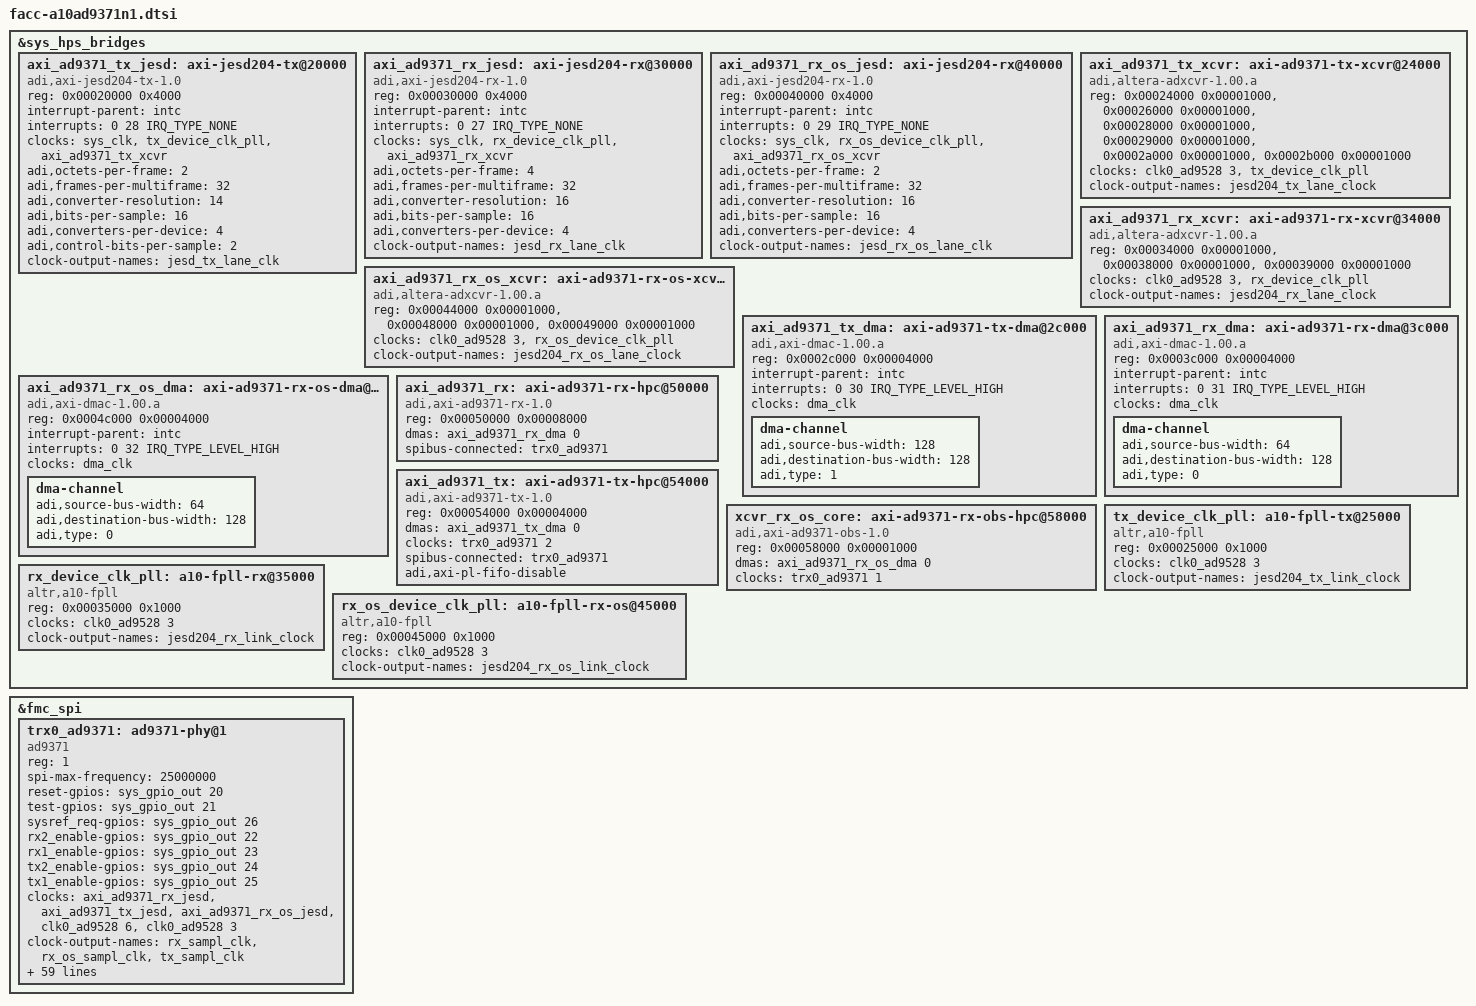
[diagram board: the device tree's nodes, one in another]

&sys_hps_bridges {
	axi_ad9371_tx_jesd: axi-jesd204-tx@20000 {
		compatible = "adi,axi-jesd204-tx-1.0";
		reg = <0x00020000 0x4000>;

		interrupt-parent = <&intc>;
		interrupts = <0 28 IRQ_TYPE_NONE>;

		clocks = <&sys_clk>, <&tx_device_clk_pll>, <&axi_ad9371_tx_xcvr>;
		clock-names = "s_axi_aclk", "device_clk", "lane_clk";

		adi,octets-per-frame = <2>;
		adi,frames-per-multiframe = <32>;
		adi,converter-resolution = <14>;
		adi,bits-per-sample = <16>;
		adi,converters-per-device = <4>;
		adi,control-bits-per-sample = <2>;

		#clock-cells = <0>;
		clock-output-names = "jesd_tx_lane_clk";
	};

	axi_ad9371_rx_jesd: axi-jesd204-rx@30000 {
		compatible = "adi,axi-jesd204-rx-1.0";
		reg = <0x00030000 0x4000>;

		interrupt-parent = <&intc>;
		interrupts = <0 27 IRQ_TYPE_NONE>;

		clocks = <&sys_clk>, <&rx_device_clk_pll>, <&axi_ad9371_rx_xcvr>;
		clock-names = "s_axi_aclk", "device_clk", "lane_clk";

		adi,octets-per-frame = <4>;
		adi,frames-per-multiframe = <32>;
		adi,converter-resolution = <16>;
		adi,bits-per-sample = <16>;
		adi,converters-per-device = <4>;

		#clock-cells = <0>;
		clock-output-names = "jesd_rx_lane_clk";
	};

	axi_ad9371_rx_os_jesd: axi-jesd204-rx@40000 {
		compatible = "adi,axi-jesd204-rx-1.0";
		reg = <0x00040000 0x4000>;

		interrupt-parent = <&intc>;
		interrupts = <0 29 IRQ_TYPE_NONE>;

		clocks = <&sys_clk>, <&rx_os_device_clk_pll>, <&axi_ad9371_rx_os_xcvr>;
		clock-names = "s_axi_aclk", "device_clk", "lane_clk";

		adi,octets-per-frame = <2>;
		adi,frames-per-multiframe = <32>;
		adi,converter-resolution = <16>;
		adi,bits-per-sample = <16>;
		adi,converters-per-device = <4>;

		#clock-cells = <0>;
		clock-output-names = "jesd_rx_os_lane_clk";
	};

	axi_ad9371_tx_xcvr: axi-ad9371-tx-xcvr@24000 {
		compatible = "adi,altera-adxcvr-1.00.a";
		reg = <0x00024000 0x00001000>,
			<0x00026000 0x00001000>,
			<0x00028000 0x00001000>,
			<0x00029000 0x00001000>,
			<0x0002a000 0x00001000>,
			<0x0002b000 0x00001000>;
		reg-names = "adxcvr", "atx-pll", "adxcfg-0", "adxcfg-1", "adxcfg-2", "adxcfg-3";

		clocks = <&clk0_ad9528 3>, <&tx_device_clk_pll>;
		clock-names = "ref", "link";

		#clock-cells = <0>;
		clock-output-names = "jesd204_tx_lane_clock";
	};

	axi_ad9371_rx_xcvr: axi-ad9371-rx-xcvr@34000 {
		compatible = "adi,altera-adxcvr-1.00.a";
		reg = <0x00034000 0x00001000>,
			<0x00038000 0x00001000>,
			<0x00039000 0x00001000>;
		reg-names = "adxcvr", "adxcfg-0", "adxcfg-1";

		clocks = <&clk0_ad9528 3>, <&rx_device_clk_pll>;
		clock-names = "ref", "link";

		#clock-cells = <0>;
		clock-output-names = "jesd204_rx_lane_clock";
	};

	axi_ad9371_rx_os_xcvr: axi-ad9371-rx-os-xcvr@44000 {
		compatible = "adi,altera-adxcvr-1.00.a";
		reg = <0x00044000 0x00001000>,
			<0x00048000 0x00001000>,
			<0x00049000 0x00001000>;
		reg-names = "adxcvr", "adxcfg-0", "adxcfg-1";

		clocks = <&clk0_ad9528 3>, <&rx_os_device_clk_pll>;
		clock-names = "ref", "link";

		#clock-cells = <0>;
		clock-output-names = "jesd204_rx_os_lane_clock";
	};

	axi_ad9371_tx_dma: axi-ad9371-tx-dma@2c000 {
		compatible = "adi,axi-dmac-1.00.a";
		reg = <0x0002c000 0x00004000>;
		interrupt-parent = <&intc>;
		interrupts = <0 30 IRQ_TYPE_LEVEL_HIGH>;
		#dma-cells = <1>;
		clocks = <&dma_clk>;

		dma-channel {
			adi,source-bus-width = <128>;
			adi,destination-bus-width = <128>;
			adi,type = <1>;
			//adi,cyclic;
		};
	};

	axi_ad9371_rx_dma: axi-ad9371-rx-dma@3c000 {
		compatible = "adi,axi-dmac-1.00.a";
		reg = <0x0003c000 0x00004000>;
		interrupt-parent = <&intc>;
		interrupts = <0 31 IRQ_TYPE_LEVEL_HIGH>;
		#dma-cells = <1>;
		clocks = <&dma_clk>;

		dma-channel {
			adi,source-bus-width = <64>;
			adi,destination-bus-width = <128>;
			adi,type = <0>;
		};
	};

	axi_ad9371_rx_os_dma: axi-ad9371-rx-os-dma@4c000 {
		compatible = "adi,axi-dmac-1.00.a";
		reg = <0x0004c000 0x00004000>;
		interrupt-parent = <&intc>;
		interrupts = <0 32 IRQ_TYPE_LEVEL_HIGH>;
		#dma-cells = <1>;
		clocks = <&dma_clk>;

		dma-channel {
			adi,source-bus-width = <64>;
			adi,destination-bus-width = <128>;
			adi,type = <0>;
		};
	};

	axi_ad9371_rx: axi-ad9371-rx-hpc@50000 {
		compatible = "adi,axi-ad9371-rx-1.0";
		reg = <0x00050000 0x00008000>;
		dmas = <&axi_ad9371_rx_dma 0>;
		dma-names = "rx";
		spibus-connected = <&trx0_ad9371>;
	};

	axi_ad9371_tx: axi-ad9371-tx-hpc@54000 {
		compatible = "adi,axi-ad9371-tx-1.0";
		reg = <0x00054000 0x00004000>;
		dmas = <&axi_ad9371_tx_dma 0>;
		dma-names = "tx";
		clocks = <&trx0_ad9371 2>;
		clock-names = "sampl_clk";
		spibus-connected = <&trx0_ad9371>;
		//adi,axi-pl-fifo-enable;/* RxDMA fifo mode */
		adi,axi-pl-fifo-disable;
	};

	xcvr_rx_os_core: axi-ad9371-rx-obs-hpc@58000 {
		compatible = "adi,axi-ad9371-obs-1.0";
		reg = <0x00058000 0x00001000>;
		dmas = <&axi_ad9371_rx_os_dma 0>;
		dma-names = "rx";
		clocks = <&trx0_ad9371 1>;
		clock-names = "sampl_clk";
	};

	tx_device_clk_pll: a10-fpll-tx@25000 {
		compatible = "altr,a10-fpll";
		reg = <0x00025000 0x1000>;
		clocks = <&clk0_ad9528 3>;

		#clock-cells = <0>;
		clock-output-names = "jesd204_tx_link_clock";
	};

	rx_device_clk_pll: a10-fpll-rx@35000 {
		compatible = "altr,a10-fpll";
		reg = <0x00035000 0x1000>;
		clocks = <&clk0_ad9528 3>;

		#clock-cells = <0>;
		clock-output-names = "jesd204_rx_link_clock";
	};

	rx_os_device_clk_pll: a10-fpll-rx-os@45000 {
		compatible = "altr,a10-fpll";
		reg = <0x00045000 0x1000>;
		clocks = <&clk0_ad9528 3>;

		#clock-cells = <0>;
		clock-output-names = "jesd204_rx_os_link_clock";
	};
};

&fmc_spi {
	trx0_ad9371: ad9371-phy@1 {
		#address-cells = <1>;
		#size-cells = <0>;
		#clock-cells = <1>;
		compatible = "ad9371";

		/* SPI Setup */
		reg = <1>;
		spi-max-frequency = <25000000>;

		reset-gpios = <&sys_gpio_out 20 0>;
		test-gpios = <&sys_gpio_out 21 0>;
		sysref_req-gpios = <&sys_gpio_out 26 0>;
		rx2_enable-gpios = <&sys_gpio_out 22 0>;
		rx1_enable-gpios = <&sys_gpio_out 23 0>;
		tx2_enable-gpios = <&sys_gpio_out 24 0>;
		tx1_enable-gpios = <&sys_gpio_out 25 0>;

		/* all interrupts in HW design should be reviewed */
		//interrupt-parent = <&intc>;
		//interrupts = <0 31 IRQ_TYPE_LEVEL_HIGH>;

		/* Clocks */
		clocks = <&axi_ad9371_rx_jesd>, <&axi_ad9371_tx_jesd>,
			<&axi_ad9371_rx_os_jesd>, <&clk0_ad9528 6>,
			<&clk0_ad9528 3>;
		clock-names = "jesd_rx_clk", "jesd_tx_clk",
			"jesd_rx_os_clk", "dev_clk", "fmc_clk";
		clock-output-names = "rx_sampl_clk", "rx_os_sampl_clk", "tx_sampl_clk";

		adi,clocks-clk-pll-vco-freq_khz = <9830400>;
		adi,clocks-device-clock_khz = <122880>;
		adi,clocks-clk-pll-hs-div = <4>;
		adi,clocks-clk-pll-vco-div = <2>;

		adi,jesd204-obs-framer-over-sample = <0>;

		adi,rx-profile-adc-div = <1>;
		adi,rx-profile-en-high-rej-dec5 = <1>;
		adi,rx-profile-iq-rate_khz = <122880>;
		adi,rx-profile-rf-bandwidth_hz = <100000000>;
		adi,rx-profile-rhb1-decimation = <1>;
		adi,rx-profile-rx-bbf-3db-corner_khz = <100000>;
		adi,rx-profile-rx-dec5-decimation = <5>;
		adi,rx-profile-rx-fir-decimation = <2>;

		adi,rx-profile-rx-fir-gain_db = <(-6)>;
		adi,rx-profile-rx-fir-num-fir-coefs = <48>;
		adi,rx-profile-rx-fir-coefs = /bits/ 16 <(-5) (-26) (32) (51) (-67) (-116) (140) (212) (-252) (-367) (429) (595) (-688) (-931) (1072) (1427) (-1650) (-2188) (2612) (3496) (-4802) (-7591) (9656) (32317) (32317) (9656) (-7591) (-4802) (3496) (2612) (-2188) (-1650) (1427) (1072) (-931) (-688) (595) (429) (-367) (-252) (212) (140) (-116) (-67) (51) (32) (-26) (-5)>;

		adi,rx-profile-custom-adc-profile = /bits/ 16  <534 386 201 98 1280 491 1591 279 1306 104 792 28 48 39 23 187>;

		adi,obs-profile-adc-div = <1>;
		adi,obs-profile-en-high-rej-dec5 = <1>;
		adi,obs-profile-iq-rate_khz = <245760>;
		adi,obs-profile-rf-bandwidth_hz = <200000000>;
		adi,obs-profile-rhb1-decimation = <1>;
		adi,obs-profile-rx-bbf-3db-corner_khz = <100000>;
		adi,obs-profile-rx-dec5-decimation = <5>;
		adi,obs-profile-rx-fir-decimation = <1>;

		adi,obs-profile-rx-fir-gain_db = <6>;
		adi,obs-profile-rx-fir-num-fir-coefs = <24>;
		adi,obs-profile-rx-fir-coefs = /bits/ 16 <(-289) (81) (-23) (-86) (229) (-354) (397) (-233) (-657) (1699) (-4172) (23010) (-4172) (1699) (-657) (-233) (397) (-354) (229) (-86) (-23) (81) (-289) (0)>;

		adi,obs-profile-custom-adc-profile = /bits/ 16  <450 349 201 98 1280 730 1626 818 1476 732 834 20 41 36 24 200>;
		adi,obs-settings-custom-loopback-adc-profile = /bits/ 16  <569 369 201 98 1280 291 1541 149 1320 58 807 34 48 40 23 189>;

		adi,tx-profile-dac-div = <1>;
		adi,tx-profile-iq-rate_khz = <245760>;
		adi,tx-profile-primary-sig-bandwidth_hz = <75000000>;
		adi,tx-profile-rf-bandwidth_hz = <200000000>;
		adi,tx-profile-thb1-interpolation = <2>;
		adi,tx-profile-thb2-interpolation = <1>;
		adi,tx-profile-tx-bbf-3db-corner_khz = <100000>;
		adi,tx-profile-tx-dac-3db-corner_khz = <187000>;
		adi,tx-profile-tx-fir-interpolation = <1>;
		adi,tx-profile-tx-input-hb-interpolation = <1>;

		adi,tx-profile-tx-fir-gain_db = <6>;
		adi,tx-profile-tx-fir-num-fir-coefs = <16>;
		adi,tx-profile-tx-fir-coefs = /bits/ 16 <(6) (-270) (203) (-168) (-84) (983) (-3222) (21143) (-3222) (983) (-84) (-168) (203) (-270) (6) (0)>;

		adi,sniffer-profile-adc-div = <1>;
		adi,sniffer-profile-en-high-rej-dec5 = <0>;
		adi,sniffer-profile-iq-rate_khz = <30720>;
		adi,sniffer-profile-rf-bandwidth_hz = <20000000>;
		adi,sniffer-profile-rhb1-decimation = <2>;
		adi,sniffer-profile-rx-bbf-3db-corner_khz = <100000>;
		adi,sniffer-profile-rx-dec5-decimation = <5>;
		adi,sniffer-profile-rx-fir-decimation = <4>;
#if 0
		/* Jacky:2018/07/25: enable pin-mode 
		   https://wiki.analog.com/resources/tools-software/linux-drivers/iio-transceiver/ad9371-customization */
		adi,arm-gpio-use-rx2-enable-pin = <1>;	// 0= RX1_ENABLE controls RX1&RX2, 1= separate RX1/RX2_ENABLE pins
		adi,arm-gpio-use-tx2-enable-pin = <1>;	// 0= TX1_ENABLE controls TX1&TX2, 1= separate TX1/TX2_ENABLE pins
		adi,arm-gpio-tx-rx-pin-mode = <1>;		// 0= ARM command mode, 1 = Pin mode to power up Tx/Rx chains
		adi,arm-gpio-orx-pin-mode = <1>;		// 0= ARM command mode, 1 = Pin mode to power up ObsRx receiver
		// to be tested: enable pin-mode but NOT enable gpio-ack
		adi,arm-gpio-orx-trigger-pin = <0>;		// Select desired GPIO pin (valid 4-15)
		adi,arm-gpio-orx-mode2-pin = <0>;		// Select desired GPIO pin (valid 0-18)
		adi,arm-gpio-orx-mode1-pin = <0>;		// Select desired GPIO pin (valid 0-18)
		adi,arm-gpio-orx-mode0-pin = <0>;		// Select desired GPIO pin (valid 0-18)
		adi,arm-gpio-rx1-enable-ack = <0>;		// Select desired GPIO pin (0-15), [4] = Output Enable
		adi,arm-gpio-rx2-enable-ack = <0>;		// Select desired GPIO pin (0-15), [4] = Output Enable
		adi,arm-gpio-tx1-enable-ack = <0>;		// Select desired GPIO pin (0-15), [4] = Output Enable
		adi,arm-gpio-tx2-enable-ack = <0>;		// Select desired GPIO pin (0-15), [4] = Output Enable
		adi,arm-gpio-orx1-enable-ack = <0>;		// Select desired GPIO pin (0-15), [4] = Output Enable
		adi,arm-gpio-orx2-enable-ack = <0>;		// Select desired GPIO pin (0-15), [4] = Output Enable
		adi,arm-gpio-srx-enable-ack = <0>;		// Select desired GPIO pin (0-15), [4] = Output Enable
		adi,arm-gpio-tx-obs-select = <0>;		// Select desired GPIO pin (0-15), [4] = Output Enable.
			// When 2 Tx are used with only 1 ORx input, this GPIO tells BBIC which Tx channel is active
			// for calibrations, so BBIC can route correct RF Tx path into the single ORx input
		adi,arm-gpio-enable-mask = <0>;
#endif
	};
};

